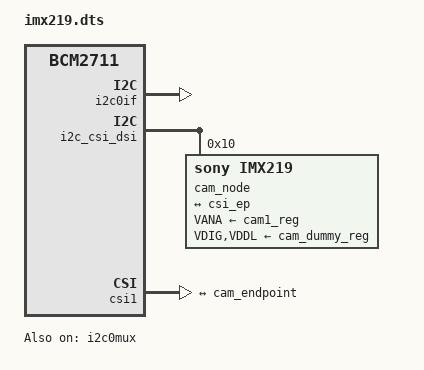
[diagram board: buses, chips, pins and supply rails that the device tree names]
// SPDX-License-Identifier: GPL-2.0-only
// Definitions for IMX219 camera module on VC I2C bus
/dts-v1/;
/plugin/;

#include <dt-bindings/gpio/gpio.h>

/ {
	compatible = "brcm,bcm2711";
};

&i2c0if {
	status = "okay";
};

&cam1_clk {
	status = "okay";
	clock-frequency = <24000000>;
};

&i2c0mux {
	status = "okay";
};

&i2c_csi_dsi {
	#address-cells = <1>;
	#size-cells = <0>;
	status = "okay";

	cam_node: imx219@10 {
		compatible = "sony,imx219";
		reg = <0x10>;

		clocks = <&cam1_clk>;
		clock-names = "xclk";

		VANA-supply = <&cam1_reg>;	/* 2.8v */
		VDIG-supply = <&cam_dummy_reg>;	/* 1.8v */
		VDDL-supply = <&cam_dummy_reg>;	/* 1.2v */

		rotation = <0>;
		orientation = <2>; /* 0 = front, 1 = rear, 2 = external */

		port {
			cam_endpoint: endpoint {
				clock-lanes = <0>;
				data-lanes = <1 2>;
				clock-noncontinuous;
				link-frequencies =
					/bits/ 64 <456000000>;
				remote-endpoint = <&csi_ep>;
			};
		};
	};

	vcm: ad5398@c {
		compatible = "adi,ad5398";
		reg = <0x0c>;
		status = "disabled";
		VANA-supply = <&cam1_reg>;
	};
};

&csi1 {
	status = "okay";
	brcm,media-controller;

	port {
		csi_ep: endpoint {
			remote-endpoint = <&cam_endpoint>;
			clock-lanes = <0>;
			data-lanes = <1 2>;
			clock-noncontinuous;
		};
	};
};
